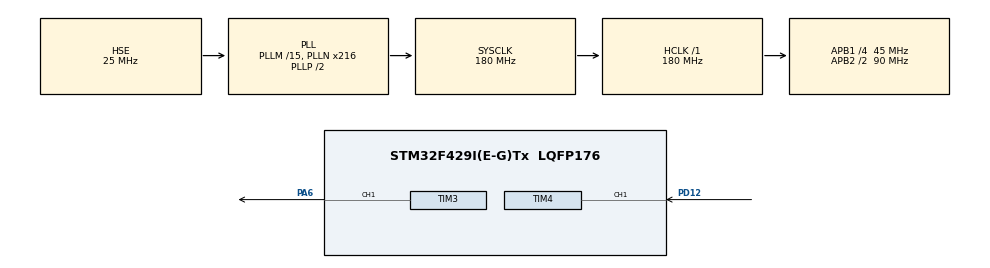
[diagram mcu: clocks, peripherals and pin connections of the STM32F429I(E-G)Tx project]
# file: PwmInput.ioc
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Mcu.Family=STM32F4
Mcu.Name=STM32F429I(E-G)Tx
Mcu.Package=LQFP176
NVIC.PriorityGroup=NVIC_PRIORITYGROUP_4
NVIC.TIM4_IRQn=true\:0\:0\:false\:false\:true\:true\:true\:true
PA13.Mode=Serial_Wire
PA13.Signal=SYS_JTMS-SWDIO
PA14.Mode=Serial_Wire
PA14.Signal=SYS_JTCK-SWCLK
PA6.Signal=S_TIM3_CH1
PD12.GPIO_PuPd=GPIO_PULLDOWN
PD12.Signal=S_TIM4_CH1
PH0/OSC_IN.Mode=HSE-External-Oscillator
PH0/OSC_IN.Signal=RCC_OSC_IN
PH1/OSC_OUT.Mode=HSE-External-Oscillator
PH1/OSC_OUT.Signal=RCC_OSC_OUT
ProjectManager.HeapSize=0x200
ProjectManager.StackSize=0x400
ProjectManager.TargetToolchain=MDK-ARM V5
RCC.48MHZClocksFreq_Value=90000000
RCC.AHBFreq_Value=180000000
RCC.APB1CLKDivider=RCC_HCLK_DIV4
RCC.APB1Freq_Value=45000000
RCC.APB1TimFreq_Value=90000000
RCC.APB2CLKDivider=RCC_HCLK_DIV2
RCC.APB2Freq_Value=90000000
RCC.APB2TimFreq_Value=180000000
RCC.CortexFreq_Value=180000000
RCC.HCLKFreq_Value=180000000
RCC.HSE_VALUE=25000000
RCC.HSI_VALUE=16000000
RCC.LSE_VALUE=32768
RCC.PLLM=15
RCC.PLLN=216
RCC.PLLSourceVirtual=RCC_PLLSOURCE_HSE
RCC.SYSCLKFreq_VALUE=180000000
RCC.SYSCLKSource=RCC_SYSCLKSOURCE_PLLCLK
RCC.VCOOutputFreq_Value=360000000
SH.S_TIM3_CH1.0=TIM3_CH1,PWM Generation1 CH1
SH.S_TIM4_CH1.0=TIM4_CH1,TriggerSource_TI1FP1
SH.S_TIM4_CH1.1=TIM4_CH1,Input_Capture1_from_TI1
TIM3.Channel-PWM\ Generation1\ CH1=TIM_CHANNEL_1
TIM3.Period=999
TIM3.Prescaler=89
TIM3.Pulse-PWM\ Generation1\ CH1=500
TIM4.Channel-Input_Capture1_from_TI1=TIM_CHANNEL_1
TIM4.Channel-Input_Capture2_from_TI1_63=TIM_CHANNEL_2
TIM4.ICPolarity_CH2=TIM_INPUTCHANNELPOLARITY_FALLING
TIM4.Prescaler=89
VP_TIM3_VS_ClockSourceINT.Mode=Internal
VP_TIM4_VS_ClockSourceINT.Mode=Internal
VP_TIM4_VS_ControllerModeReset.Mode=Reset Mode
VP_TIM4_VS_indirect_ch1.Mode=Input_Capture2_from_TI1_63
board=custom

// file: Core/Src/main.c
/* USER CODE BEGIN Header */
/**
  ******************************************************************************
  * @file           : main.c
  * @brief          : Main program body
  ******************************************************************************
  * @attention
  *
  * Copyright (c) 2025 STMicroelectronics.
  * All rights reserved.
  *
  * This software is licensed under terms that can be found in the LICENSE file
  * in the root directory of this software component.
  * If no LICENSE file comes with this software, it is provided AS-IS.
  *
  ******************************************************************************
  */
/* USER CODE END Header */
#include "main.h"
#include "tim.h"
#include "gpio.h"

/* USER CODE BEGIN PV */
uint16_t period,pulse_width;
/* USER CODE END PV */

void SystemClock_Config(void);

/* USER CODE BEGIN 0 */
void HAL_TIM_IC_CaptureCallback(TIM_HandleTypeDef *htim)
{
    if (htim->Channel == HAL_TIM_ACTIVE_CHANNEL_1) {
        // 此刻两个值都已准备好
        period = HAL_TIM_ReadCapturedValue(htim, TIM_CHANNEL_1);      // 周期
        pulse_width = HAL_TIM_ReadCapturedValue(htim, TIM_CHANNEL_2); // 脉宽
    }
}
/* USER CODE END 0 */

int main(void)
{

  /* MCU Configuration--------------------------------------------------------*/

  /* Reset of all peripherals, Initializes the Flash interface and the Systick. */
  HAL_Init();

  /* Configure the system clock */
  SystemClock_Config();

  /* Initialize all configured peripherals */
  MX_GPIO_Init();
  MX_TIM3_Init();
  MX_TIM4_Init();
  /* USER CODE BEGIN 2 */
	HAL_TIM_PWM_Start(&htim3, TIM_CHANNEL_1);
	HAL_TIM_IC_Start_IT(&htim4, TIM_CHANNEL_1);
	HAL_TIM_IC_Start(&htim4, TIM_CHANNEL_2);
  /* USER CODE END 2 */

  /* Infinite loop */
  while (1)
  {

  }
}

void SystemClock_Config(void)
{
  RCC_OscInitTypeDef RCC_OscInitStruct = {0};
  RCC_ClkInitTypeDef RCC_ClkInitStruct = {0};

  /** Configure the main internal regulator output voltage
  */
  __HAL_RCC_PWR_CLK_ENABLE();
  __HAL_PWR_VOLTAGESCALING_CONFIG(PWR_REGULATOR_VOLTAGE_SCALE1);

  /** Initializes the RCC Oscillators according to the specified parameters
  * in the RCC_OscInitTypeDef structure.
  */
  RCC_OscInitStruct.OscillatorType = RCC_OSCILLATORTYPE_HSE;
  RCC_OscInitStruct.HSEState = RCC_HSE_ON;
  RCC_OscInitStruct.PLL.PLLState = RCC_PLL_ON;
  RCC_OscInitStruct.PLL.PLLSource = RCC_PLLSOURCE_HSE;
  RCC_OscInitStruct.PLL.PLLM = 15;
  RCC_OscInitStruct.PLL.PLLN = 216;
  RCC_OscInitStruct.PLL.PLLP = RCC_PLLP_DIV2;
  RCC_OscInitStruct.PLL.PLLQ = 4;
  if (HAL_RCC_OscConfig(&RCC_OscInitStruct) != HAL_OK)
  {
    Error_Handler();
  }

  /** Activate the Over-Drive mode
  */
  if (HAL_PWREx_EnableOverDrive() != HAL_OK)
  {
    Error_Handler();
  }

  /** Initializes the CPU, AHB and APB buses clocks
  */
  RCC_ClkInitStruct.ClockType = RCC_CLOCKTYPE_HCLK|RCC_CLOCKTYPE_SYSCLK
                              |RCC_CLOCKTYPE_PCLK1|RCC_CLOCKTYPE_PCLK2;
  RCC_ClkInitStruct.SYSCLKSource = RCC_SYSCLKSOURCE_PLLCLK;
  RCC_ClkInitStruct.AHBCLKDivider = RCC_SYSCLK_DIV1;
  RCC_ClkInitStruct.APB1CLKDivider = RCC_HCLK_DIV4;
  RCC_ClkInitStruct.APB2CLKDivider = RCC_HCLK_DIV2;

  if (HAL_RCC_ClockConfig(&RCC_ClkInitStruct, FLASH_LATENCY_5) != HAL_OK)
  {
    Error_Handler();
  }
}

void Error_Handler(void)
{
  __disable_irq();
  while (1)
  {
  }
}
